# PIC32CZ2051MC70064 register map
Vendor: Microchip Technology; Series: PIC32CZMC70; File version: 0
CPU: CM7 r1p1, little endian, MPU, FPU, double-precision FPU, I-cache, D-cache, ITCM, DTCM, 3 interrupt priority bits, 69 interrupts
Registers are 32-bit, read-write, reset 0x0 unless marked. A register's access mark holds for its fields unless they carry their own. Offsets are from the block's base; [hi:lo] are bit positions; {n}, {i} and the like mark numbered series.

## ITM — Instrumentation Trace Macrocell
Base 0xE0000000
{0x0+4i} PORT_BYTE_MODE[{i}] (i=0..31) wo — ITM Stimulus Port Registers
  [7:0] PORT
{0x0+4i} PORT_HWORD_MODE[{i}] (i=0..31) wo (alternate view of PORT_BYTE_MODE[{i}]) — ITM Stimulus Port Registers
  [15:0] PORT
{0x0+4i} PORT_WORD_MODE[{i}] (i=0..31) wo (alternate view of PORT_BYTE_MODE[{i}]) — ITM Stimulus Port Registers
  [31:0] PORT
0xE00 TER — ITM Trace Enable Register
0xE40 TPR — ITM Trace Privilege Register
  [3:0] PRIVMASK
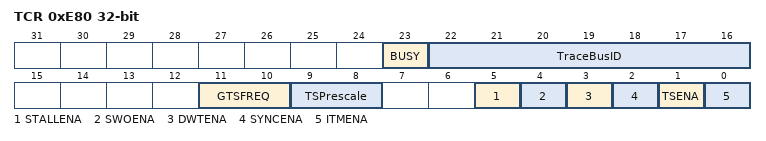
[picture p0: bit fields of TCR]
0xE80 TCR — ITM Trace Control Register
  [23] BUSY, [22:16] TraceBusID, [11:10] GTSFREQ, [9:8] TSPrescale, [5] STALLENA, [4] SWOENA, [3] DWTENA, [2] SYNCENA, [1] TSENA, [0] ITMENA

## DWT — Data Watchpoint and Trace Register
Base 0xE0001000
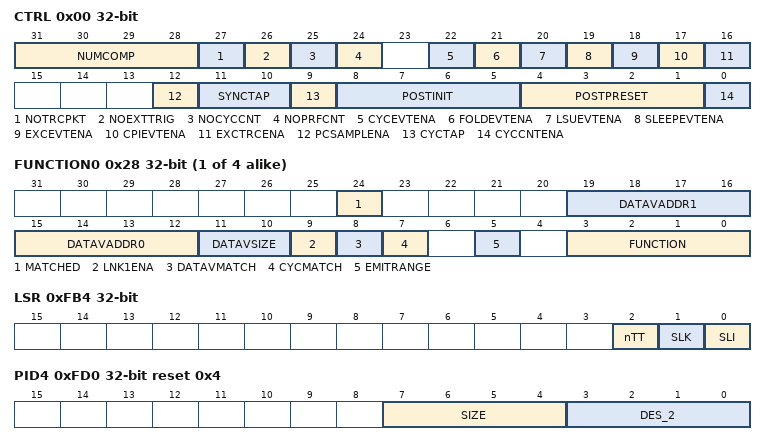
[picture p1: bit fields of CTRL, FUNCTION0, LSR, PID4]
0x00 CTRL — Control Register
  [31:28] NUMCOMP, [27] NOTRCPKT, [26] NOEXTTRIG, [25] NOCYCCNT, [24] NOPRFCNT, [22] CYCEVTENA, [21] FOLDEVTENA, [20] LSUEVTENA, [19] SLEEPEVTENA, [18] EXCEVTENA, [17] CPIEVTENA, [16] EXCTRCENA, [12] PCSAMPLENA, [11:10] SYNCTAP, [9] CYCTAP, [8:5] POSTINIT, [4:1] POSTPRESET, [0] CYCCNTENA
0x04 CYCCNT — Cycle Count Register
0x08 CPICNT — CPI Count Register
  [7:0] CPICNT
0x0C EXCCNT — Exception Overhead Count Register
  [7:0] EXCCNT
0x10 SLEEPCNT — Sleep Count Register
  [7:0] SLEEPCNT
0x14 LSUCNT — LSU Count Register
  [7:0] LSUCNT
0x18 FOLDCNT — Folded-instruction Count Register
  [7:0] FOLDCNT
0x1C PCSR ro — Program Counter Sample Register
{0x20+0x10*i} COMP{i} (i=0..3) — Comparator Register {i}
{0x24+0x10*i} MASK{i} (i=0..3) — Mask Register {i}
  [4:0] MASK
{0x28+0x10*i} FUNCTION{i} (i=0..3) — Function Register {i}
  [24] MATCHED, [19:16] DATAVADDR1, [15:12] DATAVADDR0, [11:10] DATAVSIZE, [9] LNK1ENA, [8] DATAVMATCH, [7] CYCMATCH, [5] EMITRANGE, [3:0] FUNCTION
0xFB0 LAR wo — DWT Software Lock Access Register
  [31:0] KEY — Lock access control
    0xC5ACCE55=UNLOCK (Unlock key value)
0xFB4 LSR ro — DWT Software Lock Status Register
  [2] nTT — Not thirty-two bit
  [1] SLK — Software Lock status
  [0] SLI — Software Lock implemented
0xFD0 PID4 ro reset 0x4 — DWT Peripheral Identification Register 4
  [7:4] SIZE — 4KB count
  [3:0] DES_2 — JEP106 continuation code
{0xFC0+4i} PID{i} ro (i=5..7) — DWT Peripheral Identification Register {i}
0xFE0 PID0 ro reset 0x2 — DWT Peripheral Identification Register 0
  [7:0] PART_0 — Part number bits[7:0]
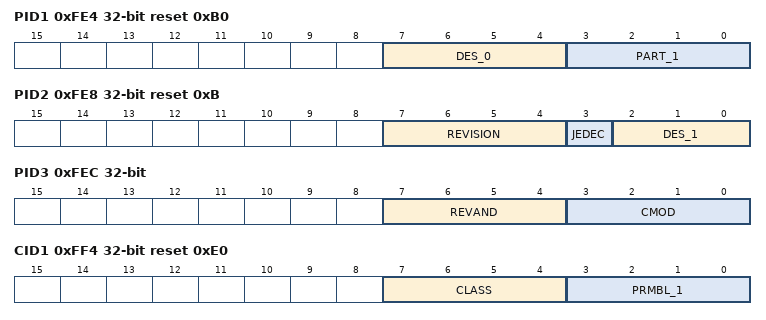
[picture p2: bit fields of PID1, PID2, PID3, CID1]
0xFE4 PID1 ro reset 0xB0 — DWT Peripheral Identification Register 1
  [7:4] DES_0 — JEP106 identification code bits [3:0]
  [3:0] PART_1 — Part number bits[11:8]
0xFE8 PID2 ro reset 0xB — DWT Peripheral Identification Register 2
  [7:4] REVISION — Component revision
  [3] JEDEC — JEDEC assignee value is used
  [2:0] DES_1 — JEP106 identification code bits[6:4]
0xFEC PID3 ro — DWT Peripheral Identification Register 3
  [7:4] REVAND
  [3:0] CMOD — Customer Modified
0xFF0 CID0 ro reset 0xD — DWT Component Identification Register 0
  [7:0] PRMBL_0 — CoreSight component identification preamble
0xFF4 CID1 ro reset 0xE0 — DWT Component Identification Register 1
  [7:4] CLASS — CoreSight component class
  [3:0] PRMBL_1 — CoreSight component identification preamble
0xFF8 CID2 ro reset 0x5 — DWT Component Identification Register 2
  [7:0] PRMBL_2 — CoreSight component identification preamble
0xFFC CID3 ro reset 0xB1 — DWT Component Identification Register 3
  [7:0] PRMBL_3 — CoreSight component identification preamble

## FPB — Flash Patch and Breakpoint
Base 0xE0002000
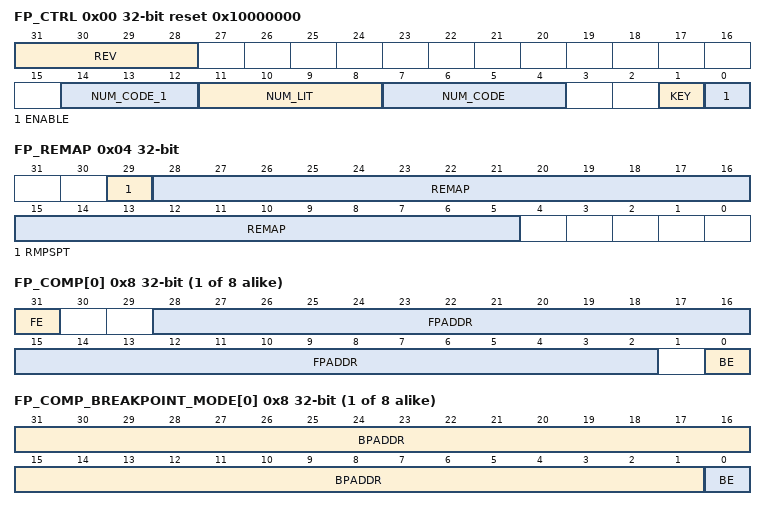
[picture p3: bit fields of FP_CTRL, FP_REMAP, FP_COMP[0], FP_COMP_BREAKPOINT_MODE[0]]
0x00 FP_CTRL reset 0x10000000 — Flash Patch Control Register
  [31:28] REV — Revision
  [14:12] NUM_CODE_1 — Number of implemented code comparators bits [6:4]
  [11:8] NUM_LIT — Number of literal comparators
  [7:4] NUM_CODE — Number of implemented code comparators bits [3:0]
  [1] KEY — FP_CTRL write-enable key
  [0] ENABLE — Flash Patch global enable
0x04 FP_REMAP ro — Flash Patch Remap Register
  [29] RMPSPT — Remap supported
  [28:5] REMAP — Remap address
{0x8+4i} FP_COMP[{i}] (i=0..7) — Flash Patch Comparator Register n
  [31] FE — Flash Patch enable
  [28:2] FPADDR — Flash Patch address
  [0] BE — Breakpoint enable
{0x8+4i} FP_COMP_BREAKPOINT_MODE[{i}] (i=0..7) (alternate view of FP_COMP[{i}]) — Flash Patch Comparator Register n
  [31:1] BPADDR — Breakpoint address
  [0] BE — Breakpoint enable
0xFB0 FP_LAR wo — FPB Software Lock Access Register
  [31:0] KEY — Lock access control
    0xC5ACCE55=UNLOCK (Unlock key value)
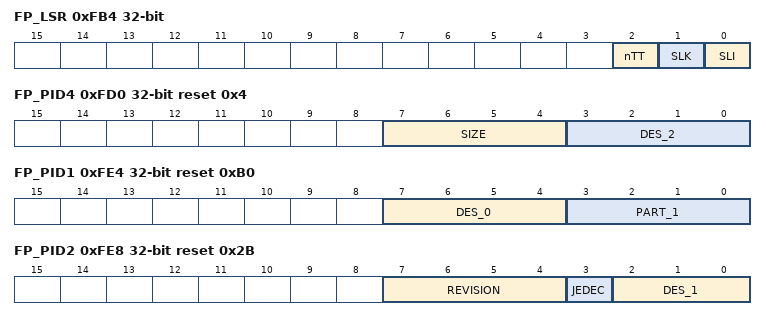
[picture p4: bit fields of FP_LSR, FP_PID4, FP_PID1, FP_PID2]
0xFB4 FP_LSR ro — FPB Software Lock Status Register
  [2] nTT — Not thirty-two bit
  [1] SLK — Software Lock status
  [0] SLI — Software Lock implemented
0xFD0 FP_PID4 ro reset 0x4 — FP Peripheral Identification Register 4
  [7:4] SIZE — 4KB count
  [3:0] DES_2 — JEP106 continuation code
{0xFC0+4i} FP_PID{i} ro (i=5..7) — FP Peripheral Identification Register {i}
0xFE0 FP_PID0 ro — FP Peripheral Identification Register 0
  [7:0] PART_0 — Part number bits[7:0]
0xFE4 FP_PID1 ro reset 0xB0 — FP Peripheral Identification Register 1
  [7:4] DES_0 — JEP106 identification code bits [3:0]
  [3:0] PART_1 — Part number bits[11:8]
0xFE8 FP_PID2 ro reset 0x2B — FP Peripheral Identification Register 2
  [7:4] REVISION — Component revision
  [3] JEDEC — JEDEC assignee value is used
  [2:0] DES_1 — JEP106 identification code bits[6:4]
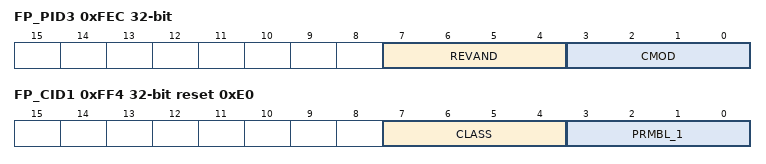
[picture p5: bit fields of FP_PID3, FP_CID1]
0xFEC FP_PID3 ro — FP Peripheral Identification Register 3
  [7:4] REVAND
  [3:0] CMOD — Customer Modified
0xFF0 FP_CID0 ro reset 0xD — FP Component Identification Register 0
  [7:0] PRMBL_0 — CoreSight component identification preamble
0xFF4 FP_CID1 ro reset 0xE0 — FP Component Identification Register 1
  [7:4] CLASS — CoreSight component class
  [3:0] PRMBL_1 — CoreSight component identification preamble
0xFF8 FP_CID2 ro reset 0x5 — FP Component Identification Register 2
  [7:0] PRMBL_2 — CoreSight component identification preamble
0xFFC FP_CID3 ro reset 0xB1 — FP Component Identification Register 3
  [7:0] PRMBL_3 — CoreSight component identification preamble

## Notices in the file
Copyright (c) 2026 Microchip Technology Inc.
SPDX-License-Identifier: Apache-2.0
Licensed under the Apache License, Version 2.0 (the "License");
you may not use this file except in compliance with the License.
You may obtain a copy of the License at
http://www.apache.org/licenses/LICENSE-2.0
Unless required by applicable law or agreed to in writing, software
distributed under the License is distributed on an "AS IS" BASIS,
WITHOUT WARRANTIES OR CONDITIONS OF ANY KIND, either express or implied.
See the License for the specific language governing permissions and
limitations under the License.
